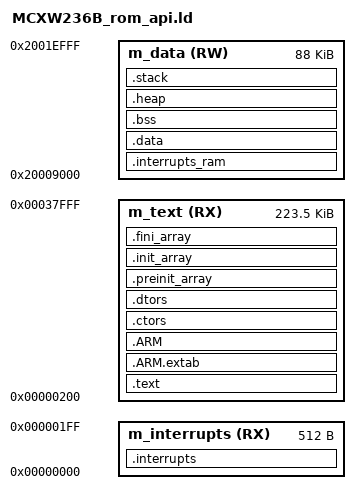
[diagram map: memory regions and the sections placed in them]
/*
** ###################################################################
**     Processors:          NHS52S04HN40
**                          NHS52S04UK37
**
**     Compiler:            GNU C Compiler
**
**
**     Copyright 2016 Freescale Semiconductor, Inc.
**     Copyright 2021, 2023 NXP
**     This software is owned or controlled by NXP and may only be used
**     strictly in accordance with the applicable license terms.  By expressly
**     accepting such terms or by downloading, installing, activating and/or
**     otherwise using the software, you are agreeing that you have read, and
**     that you agree to comply with and are bound by, such license terms.  If
**     you do not agree to be bound by the applicable license terms, then you
**     may not retain, install, activate or otherwise use the software.
**
** ###################################################################
*/

GROUP(libgcc.a libc.a libm.a libnosys.a libc_nano.a)

/* Entry Point */
ENTRY(Reset_Handler)

HEAP_SIZE  = DEFINED(__heap_size__)  ? __heap_size__  : 0x0400;
STACK_SIZE = DEFINED(__stack_size__) ? __stack_size__ : 0x0800;
M_VECTOR_RAM_SIZE = 0x00000140;

/* Specify the memory areas */
/* 112k (SRAM0 = 16k, SRAM1 = 32k, SRAM2 = 64K) RAM to fit data segment */
/* First 16K (from 0x20004000 until 0x20008000) ram should should not be used because is used by ROM API functions */
/* Next 4K (from 0x20008000 until 0x20009000), ram should not be used because it is used by mbedTLS ROM functions */
/* Next 88K (from 0x20009000 until 0x2001F000)*, ram is used for data memory */
/* Last 4K (from 0x2001F000 until 0x20020000) ram is used to put code (typically interrupts, because interrupts cannot be executed from flash while flash IAP functions are executed)*/
MEMORY
{
  m_interrupts          (RX)  : ORIGIN = 0x00000000, LENGTH = 0x00000200
  m_text                (RX)  : ORIGIN = 0x00000200, LENGTH = 0x00037E00
  m_data                (RW)  : ORIGIN = 0x20009000, LENGTH = 0x00016000
  /* Create a RAM section that can be used to place code (typically interrupts, because interrupts cannot be executed from flash while flash IAP functions are executed)*/
}

/* Define output sections */
SECTIONS
{
  /* The startup code goes first into internal flash */
  .interrupts :
  {
    __VECTOR_TABLE = .;
    __Vectors = .;
    . = ALIGN(4);
    KEEP(*(.isr_vector))     /* Startup code */
    . = ALIGN(4);
    /* Global Section Table */
		. = ALIGN(4) ;
		__section_table_start = .;
		__data_section_table = .;
		LONG(LOADADDR(.data));
		LONG(    ADDR(.data)) ;
		LONG(  SIZEOF(.data));
		__data_section_table_end = .;
		__bss_section_table = .;
		LONG(    ADDR(.bss));
		LONG(  SIZEOF(.bss));
		__bss_section_table_end = .;
		__section_table_end = . ;
		/* End of Global Section Table */
  } > m_interrupts

  .interrupts_ram :
  {
    . = ALIGN(4);
    __interrupts_ram_start__ = .; /* Create a global symbol at data start */
    *(.m_interrupts_ram)     /* This is a user defined section */
    . += M_VECTOR_RAM_SIZE;
    . = ALIGN(4);
    __interrupts_ram_end__ = .; /* Define a global symbol at data end */
  } > m_data
  __RAM_VECTOR_TABLE_SIZE_BYTES = (__interrupts_ram_end__ - __interrupts_ram_start__);

  /* The program code and other data goes into internal flash */
  .text :
  {
    . = ALIGN(4);
    *(.text)                 /* .text sections (code) */
    *(.text*)                /* .text* sections (code) */
    *(.rodata)               /* .rodata sections (constants, strings, etc.) */
    *(.rodata*)              /* .rodata* sections (constants, strings, etc.) */
    *(.glue_7)               /* glue arm to thumb code */
    *(.glue_7t)              /* glue thumb to arm code */
    *(.eh_frame)
    KEEP (*(.init))
    KEEP (*(.fini))
    . = ALIGN(4);
  } > m_text
  
  .ARM.extab :
  {
    *(.ARM.extab* .gnu.linkonce.armextab.*)
  } > m_text

  .ARM :
  {
    __exidx_start = .;
    *(.ARM.exidx*)
    __exidx_end = .;
  } > m_text

 .ctors :
  {
    __CTOR_LIST__ = .;
    /* gcc uses crtbegin.o to find the start of
       the constructors, so we make sure it is
       first.  Because this is a wildcard, it
       doesn't matter if the user does not
       actually link against crtbegin.o; the
       linker won't look for a file to match a
       wildcard.  The wildcard also means that it
       doesn't matter which directory crtbegin.o
       is in.  */
    KEEP (*crtbegin.o(.ctors))
    KEEP (*crtbegin?.o(.ctors))
    /* We don't want to include the .ctor section from
       from the crtend.o file until after the sorted ctors.
       The .ctor section from the crtend file contains the
       end of ctors marker and it must be last */
    KEEP (*(EXCLUDE_FILE(*crtend?.o *crtend.o) .ctors))
    KEEP (*(SORT(.ctors.*)))
    KEEP (*(.ctors))
    __CTOR_END__ = .;
  } > m_text

  .dtors :
  {
    __DTOR_LIST__ = .;
    KEEP (*crtbegin.o(.dtors))
    KEEP (*crtbegin?.o(.dtors))
    KEEP (*(EXCLUDE_FILE(*crtend?.o *crtend.o) .dtors))
    KEEP (*(SORT(.dtors.*)))
    KEEP (*(.dtors))
    __DTOR_END__ = .;
  } > m_text

  .preinit_array :
  {
    PROVIDE_HIDDEN (__preinit_array_start = .);
    KEEP (*(.preinit_array*))
    PROVIDE_HIDDEN (__preinit_array_end = .);
  } > m_text

  .init_array :
  {
    PROVIDE_HIDDEN (__init_array_start = .);
    KEEP (*(SORT(.init_array.*)))
    KEEP (*(.init_array*))
    PROVIDE_HIDDEN (__init_array_end = .);
  } > m_text

  .fini_array :
  {
    PROVIDE_HIDDEN (__fini_array_start = .);
    KEEP (*(SORT(.fini_array.*)))
    KEEP (*(.fini_array*))
    PROVIDE_HIDDEN (__fini_array_end = .);
  } > m_text    
  
  __etext = .;    /* define a global symbol at end of code */
  __DATA_ROM = .; /* Symbol is used by startup for data initialization */

  .data : AT(__DATA_ROM)
  {
    . = ALIGN(4);
    __DATA_RAM = .;
    __data_start__ = .;      /* create a global symbol at data start */
    *(.ramfunc*)             /* for functions in ram */
    *(.data)                 /* .data sections */
    *(.data*)                /* .data* sections */
    KEEP(*(.jcr*))
    . = ALIGN(4);
    __data_end__ = .;        /* define a global symbol at data end */
  } > m_data

  __DATA_END = __DATA_ROM + (__data_end__ - __data_start__);
  text_end = ORIGIN(m_text) + LENGTH(m_text);
  ASSERT(__DATA_END <= text_end, "region m_text overflowed with text and data")

  /* Uninitialized data section */
  .bss :
  {
    /* This is used by the startup in order to initialize the .bss section */
    . = ALIGN(4);
    __START_BSS = .;
    __bss_start__ = .;
    *(.bss)
    *(.bss*)
    *(COMMON)
    . = ALIGN(4);
    __bss_end__ = .;
    __END_BSS = .;
  } > m_data

  .heap :
  {
    . = ALIGN(8);
    __end__ = .;
    PROVIDE(end = .);
    __HeapBase = .;
    . += HEAP_SIZE;
    __HeapLimit = .;
    _pvHeapLimit = .;
    __heap_limit = .; /* Add for _sbrk */
  } > m_data

  .stack :
  {
    . = ALIGN(8);
    . += STACK_SIZE;
  } > m_data   
  
  /* Initializes stack on the end of block */
  __StackTop   = ORIGIN(m_data) + LENGTH(m_data);
  __StackLimit = __StackTop - STACK_SIZE;
  PROVIDE(__stack = __StackTop);

  .ARM.attributes 0 : { *(.ARM.attributes) }

  ASSERT(__StackLimit >= __HeapLimit, "region m_data overflowed with stack and heap")   
}

